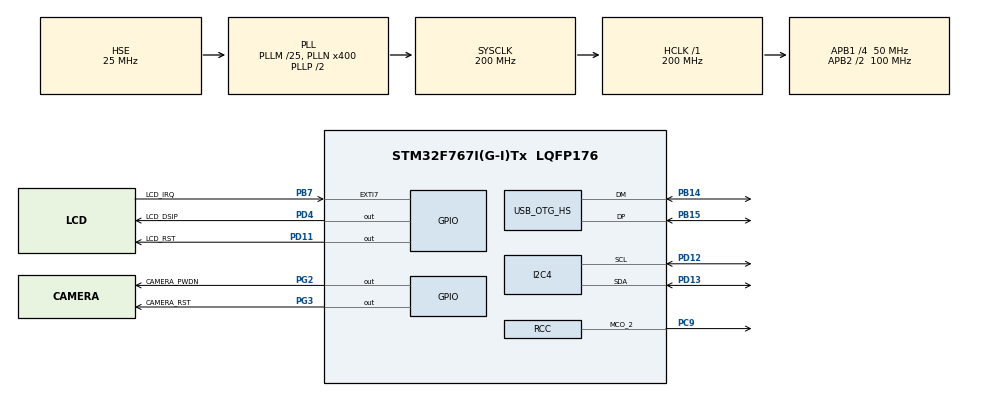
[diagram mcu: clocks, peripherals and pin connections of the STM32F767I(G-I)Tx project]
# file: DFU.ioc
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I2C4.Timing=0x00C0EAFF
Mcu.Family=STM32F7
Mcu.Name=STM32F767I(G-I)Tx
Mcu.Package=LQFP176
NVIC.OTG_HS_IRQn=true\:1\:0\:true\:false\:true\:false\:true
NVIC.PriorityGroup=NVIC_PRIORITYGROUP_4
NVIC.TIM1_UP_TIM10_IRQn=true\:0\:0\:false\:false\:true\:false\:true
NVIC.TimeBase=TIM1_UP_TIM10_IRQn
NVIC.TimeBaseIP=TIM1
PA0/WKUP.Mode=SYS_WakeUp0
PA0/WKUP.Signal=SYS_WKUP1
PA1.Signal=ETH_REF_CLK
PA10.Signal=USART1_RX
PA11.GPIO_Speed=GPIO_SPEED_FREQ_VERY_HIGH
PA11.Signal=LTDC_R4
PA12.GPIO_Speed=GPIO_SPEED_FREQ_VERY_HIGH
PA12.Signal=LTDC_R5
PA13.Mode=Serial_Wire
PA13.Signal=SYS_JTMS-SWDIO
PA14.Mode=Serial_Wire
PA14.Signal=SYS_JTCK-SWCLK
PA15.Signal=SYS_JTDI
PA2.Signal=ETH_MDIO
PA3.GPIO_Speed=GPIO_SPEED_FREQ_VERY_HIGH
PA3.Signal=LTDC_B5
PA4.Signal=DCMI_HSYNC
PA6.Signal=DCMI_PIXCLK
PA7.Signal=ETH_CRS_DV
PA8.Signal=RCC_MCO_1
PA9.Signal=USART1_TX
PB0.GPIO_Speed=GPIO_SPEED_FREQ_VERY_HIGH
PB0.Signal=LTDC_R3
PB1.GPIO_Speed=GPIO_SPEED_FREQ_VERY_HIGH
PB1.Signal=LTDC_R6
PB10.Signal=USART3_TX
PB11.Signal=ETH_TX_EN
PB14.Mode=Device_Only_FS
PB14.Signal=USB_OTG_HS_DM
PB15.Mode=Device_Only_FS
PB15.Signal=USB_OTG_HS_DP
PB2.Signal=QUADSPI_CLK
PB3.Signal=SYS_JTDO-SWO
PB4.Signal=SYS_JTRST
PB6.Signal=QUADSPI_BK1_NCS
PB7.GPIO_Label=LCD_IRQ
PB7.Signal=GPXTI7
PB8.GPIO_Speed=GPIO_SPEED_FREQ_VERY_HIGH
PB8.Signal=LTDC_B6
PB9.GPIO_Speed=GPIO_SPEED_FREQ_VERY_HIGH
PB9.Signal=LTDC_B7
PC0.Signal=FMC_SDNWE
PC1.Signal=ETH_MDC
PC10.Signal=SDMMC1_D2
PC11.Signal=SDMMC1_D3
PC12.Signal=SDMMC1_CK
PC13.Signal=RTC_TAMP1
PC14/OSC32_IN.Mode=LSE-External-Oscillator
PC14/OSC32_IN.Signal=RCC_OSC32_IN
PC15/OSC32_OUT.Mode=LSE-External-Oscillator
PC15/OSC32_OUT.Signal=RCC_OSC32_OUT
PC4.Signal=ETH_RXD0
PC5.Signal=ETH_RXD1
PC7.GPIO_Speed=GPIO_SPEED_FREQ_VERY_HIGH
PC7.Signal=LTDC_G6
PC8.Signal=SDMMC1_D0
PC9.Mode=Clock-out-2
PC9.Signal=RCC_MCO_2
PD0.Signal=FMC_D2_DA2
PD1.Signal=FMC_D3_DA3
PD10.Signal=FMC_D15_DA15
PD11.GPIO_Label=LCD_RST
PD11.Signal=GPIO_Output
PD12.Mode=I2C
PD12.Signal=I2C4_SCL
PD13.Mode=I2C
PD13.Signal=I2C4_SDA
PD14.Signal=FMC_D0_DA0
PD15.Signal=FMC_D1_DA1
PD2.Signal=SDMMC1_CMD
PD3.Signal=DCMI_D5
PD4.GPIO_Label=LCD_DSIP
PD4.Signal=GPIO_Output
PD5.Signal=USART2_TX
PD6.GPIO_Speed=GPIO_SPEED_FREQ_VERY_HIGH
PD6.Signal=LTDC_B2
PD8.Signal=FMC_D13_DA13
PD9.Signal=FMC_D14_DA14
PE0.Signal=FMC_NBL0
PE1.Signal=FMC_NBL1
PE10.Signal=FMC_D7_DA7
PE11.Signal=FMC_D8_DA8
PE12.Signal=FMC_D9_DA9
PE13.Signal=FMC_D10_DA10
PE14.Signal=FMC_D11_DA11
PE15.Signal=FMC_D12_DA12
PE4.GPIO_Speed=GPIO_SPEED_FREQ_VERY_HIGH
PE4.Signal=LTDC_B0
PE5.GPIO_Speed=GPIO_SPEED_FREQ_VERY_HIGH
PE5.Signal=LTDC_G0
PE6.GPIO_Speed=GPIO_SPEED_FREQ_VERY_HIGH
PE6.Signal=LTDC_G1
PE7.Signal=FMC_D4_DA4
PE8.Signal=FMC_D5_DA5
PE9.Signal=FMC_D6_DA6
PF0.Signal=FMC_A0
PF1.Signal=FMC_A1
PF10.GPIO_Speed=GPIO_SPEED_FREQ_VERY_HIGH
PF10.Signal=LTDC_DE
PF11.Signal=FMC_SDNRAS
PF12.Signal=FMC_A6
PF13.Signal=FMC_A7
PF14.Signal=FMC_A8
PF15.Signal=FMC_A9
PF2.Signal=FMC_A2
PF3.Signal=FMC_A3
PF4.Signal=FMC_A4
PF5.Signal=FMC_A5
PF6.Signal=QUADSPI_BK1_IO3
PF7.Signal=QUADSPI_BK1_IO2
PF8.Signal=QUADSPI_BK1_IO0
PF9.Signal=QUADSPI_BK1_IO1
PG0.Signal=FMC_A10
PG1.Signal=FMC_A11
PG10.GPIO_Speed=GPIO_SPEED_FREQ_VERY_HIGH
PG10.Signal=LTDC_G3
PG11.GPIO_Speed=GPIO_SPEED_FREQ_VERY_HIGH
PG11.Signal=LTDC_B3
PG12.GPIO_Speed=GPIO_SPEED_FREQ_VERY_HIGH
PG12.Signal=LTDC_B1
PG13.Signal=ETH_TXD0
PG14.Signal=ETH_TXD1
PG15.Signal=FMC_SDNCAS
PG2.GPIO_Label=CAMERA_PWDN
PG2.Signal=GPIO_Output
PG3.GPIO_Label=CAMERA_RST
PG3.Signal=GPIO_Output
PG4.Signal=FMC_A14_BA0
PG5.Signal=FMC_A15_BA1
PG6.GPIO_Speed=GPIO_SPEED_FREQ_VERY_HIGH
PG6.Signal=LTDC_R7
PG7.GPIO_Speed=GPIO_SPEED_FREQ_VERY_HIGH
PG7.Signal=LTDC_CLK
PG8.Signal=FMC_SDCLK
PH0/OSC_IN.Mode=HSE-External-Oscillator
PH0/OSC_IN.Signal=RCC_OSC_IN
PH1/OSC_OUT.Mode=HSE-External-Oscillator
PH1/OSC_OUT.Signal=RCC_OSC_OUT
PH10.Signal=DCMI_D1
PH11.Signal=DCMI_D2
PH12.Signal=DCMI_D3
PH13.GPIO_Speed=GPIO_SPEED_FREQ_VERY_HIGH
PH13.Signal=LTDC_G2
PH14.Signal=DCMI_D4
PH15.GPIO_Speed=GPIO_SPEED_FREQ_VERY_HIGH
PH15.Signal=LTDC_G4
PH2.GPIO_Speed=GPIO_SPEED_FREQ_VERY_HIGH
PH2.Signal=LTDC_R0
PH3.GPIO_Speed=GPIO_SPEED_FREQ_VERY_HIGH
PH3.Signal=LTDC_R1
PH4.Signal=I2C2_SCL
PH5.Signal=I2C2_SDA
PH6.Signal=FMC_SDNE1
PH7.Signal=FMC_SDCKE1
PH8.GPIO_Speed=GPIO_SPEED_FREQ_VERY_HIGH
PH8.Signal=LTDC_R2
PH9.Signal=DCMI_D0
PI0.GPIO_Speed=GPIO_SPEED_FREQ_VERY_HIGH
PI0.Signal=LTDC_G5
PI10.GPIO_Speed=GPIO_SPEED_FREQ_VERY_HIGH
PI10.Signal=LTDC_HSYNC
PI2.GPIO_Speed=GPIO_SPEED_FREQ_VERY_HIGH
PI2.Signal=LTDC_G7
PI4.GPIO_Speed=GPIO_SPEED_FREQ_VERY_HIGH
PI4.Signal=LTDC_B4
PI5.Signal=DCMI_VSYNC
PI6.Signal=DCMI_D6
PI7.Signal=DCMI_D7
PI9.GPIO_Speed=GPIO_SPEED_FREQ_VERY_HIGH
PI9.Signal=LTDC_VSYNC
ProjectManager.HeapSize=0x1000
ProjectManager.StackSize=0x1000
ProjectManager.TargetToolchain=MDK-ARM V5
RCC.AHBFreq_Value=200000000
RCC.APB1CLKDivider=RCC_HCLK_DIV4
RCC.APB1Freq_Value=50000000
RCC.APB1TimFreq_Value=100000000
RCC.APB2CLKDivider=RCC_HCLK_DIV2
RCC.APB2Freq_Value=100000000
RCC.APB2TimFreq_Value=200000000
RCC.CortexFreq_Value=200000000
RCC.EnbaleCSS=true
RCC.HCLKFreq_Value=200000000
RCC.HSE_VALUE=25000000
RCC.HSI_VALUE=16000000
RCC.PLL48CLockSelection=RCC_CLK48SOURCE_PLLSAIP
RCC.PLLI2SR=4
RCC.PLLM=25
RCC.PLLN=400
RCC.PLLQ=8
RCC.PLLSAIN=288
RCC.PLLSAIP=RCC_PLLSAIP_DIV6
RCC.PLLSAIR=3
RCC.PLLSourceVirtual=RCC_PLLSOURCE_HSE
RCC.RCC_MCO1Source=RCC_MCO1SOURCE_PLLCLK
RCC.RCC_MCO2Source=RCC_MCO2SOURCE_PLLI2SCLK
RCC.RCC_MCODiv1=RCC_MCODIV_4
RCC.RCC_MCODiv2=RCC_MCODIV_2
RCC.RTCClockSelection=RCC_RTCCLKSOURCE_LSE
RCC.SDMMCClockSelection=RCC_SDMMC1CLKSOURCE_CLK48
RCC.SYSCLKFreq_VALUE=200000000
RCC.SYSCLKSource=RCC_SYSCLKSOURCE_PLLCLK
RCC.USART1CLockSelection=RCC_USART1CLKSOURCE_SYSCLK
RCC.USBFreq_Value=48000000
RCC.VCOOutputFreq_Value=400000000
SH.FMC_A0.0=FMC_A0
SH.FMC_A1.0=FMC_A1
SH.FMC_A10.0=FMC_A10
SH.FMC_A11.0=FMC_A11
SH.FMC_A14_BA0.0=FMC_BA0
SH.FMC_A15_BA1.0=FMC_BA1
SH.FMC_A2.0=FMC_A2
SH.FMC_A3.0=FMC_A3
SH.FMC_A4.0=FMC_A4
SH.FMC_A5.0=FMC_A5
SH.FMC_A6.0=FMC_A6
SH.FMC_A7.0=FMC_A7
SH.FMC_A8.0=FMC_A8
SH.FMC_A9.0=FMC_A9
SH.FMC_D0_DA0.0=FMC_DA0
SH.FMC_D0_DA0.1=FMC_D0
SH.FMC_D10_DA10.0=FMC_DA10
SH.FMC_D10_DA10.1=FMC_D10
SH.FMC_D11_DA11.0=FMC_DA11
SH.FMC_D11_DA11.1=FMC_D11
SH.FMC_D12_DA12.0=FMC_DA12
SH.FMC_D12_DA12.1=FMC_D12
SH.FMC_D13_DA13.0=FMC_DA13
SH.FMC_D13_DA13.1=FMC_D13
SH.FMC_D14_DA14.0=FMC_DA14
SH.FMC_D14_DA14.1=FMC_D14
SH.FMC_D15_DA15.0=FMC_DA15
SH.FMC_D15_DA15.1=FMC_D15
SH.FMC_D1_DA1.0=FMC_DA1
SH.FMC_D1_DA1.1=FMC_D1
SH.FMC_D2_DA2.0=FMC_DA2
SH.FMC_D2_DA2.1=FMC_D2
SH.FMC_D3_DA3.0=FMC_DA3
SH.FMC_D3_DA3.1=FMC_D3
SH.FMC_D4_DA4.0=FMC_DA4
SH.FMC_D4_DA4.1=FMC_D4
SH.FMC_D5_DA5.0=FMC_DA5
SH.FMC_D5_DA5.1=FMC_D5
SH.FMC_D6_DA6.0=FMC_DA6
SH.FMC_D6_DA6.1=FMC_D6
SH.FMC_D7_DA7.0=FMC_DA7
SH.FMC_D7_DA7.1=FMC_D7
SH.FMC_D8_DA8.0=FMC_DA8
SH.FMC_D8_DA8.1=FMC_D8
SH.FMC_D9_DA9.0=FMC_DA9
SH.FMC_D9_DA9.1=FMC_D9
SH.FMC_NBL0.0=FMC_NBL0
SH.FMC_NBL1.0=FMC_NBL1
SH.FMC_SDCLK.0=FMC_SDCLK
SH.FMC_SDNCAS.0=FMC_SDNCAS
SH.FMC_SDNRAS.0=FMC_SDNRAS
SH.FMC_SDNWE.0=FMC_SDNWE
USB_DEVICE.CLASS_NAME_HS=DFU
USB_DEVICE.USBD_DFU_APP_DEFAULT_ADD-DFU_HS=0x08008000
USB_DEVICE.USBD_DFU_MEDIA-DFU_HS=@Internal Flash   /0x08000000/01*032Ka,03*032Kg,01*128Kg,03*256Kg
USB_DEVICE.VirtualMode-DFU_HS=Dfu
USB_DEVICE.VirtualModeHS=Dfu_HS
USB_OTG_HS.VirtualMode-Device_Only_FS=Device_Only_FS
VP_SYS_VS_tim1.Mode=TIM1
VP_USB_DEVICE_VS_USB_DEVICE_DFU_HS.Mode=DFU_HS
board=custom

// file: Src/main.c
/* USER CODE BEGIN Header */
/**
  ******************************************************************************
  * @file           : main.c
  * @brief          : Main program body
  ******************************************************************************
  * @attention
  *
  * <h2><center>&copy; Copyright (c) 2020 STMicroelectronics.
  * All rights reserved.</center></h2>
  *
  * This software component is licensed by ST under Ultimate Liberty license
  * SLA0044, the "License"; You may not use this file except in compliance with
  * the License. You may obtain a copy of the License at:
  *                             www.st.com/SLA0044
  *
  ******************************************************************************
  */
/* USER CODE END Header */

#include "main.h"
#include "usb_device.h"

/* USER CODE BEGIN Includes */

#include "usbd_core.h"
#include "usbd_desc.h"
#include "usbd_dfu.h"
#include "usbd_dfu_if.h"

/* USER CODE END Includes */

I2C_HandleTypeDef hi2c4;

/* USER CODE BEGIN PV */

pFunction JumpToApplication;
uint32_t JumpAddress;

/* USER CODE END PV */

void SystemClock_Config(void);
static void MX_GPIO_Init(void);
static void MX_I2C4_Init(void);

int main(void)
{

  /* MCU Configuration--------------------------------------------------------*/

  /* Reset of all peripherals, Initializes the Flash interface and the Systick. */
  HAL_Init();

  /* Configure the system clock */
  SystemClock_Config();

  /* USER CODE BEGIN SysInit */

  /* Check if the KEY Button is pressed */
  if(HAL_GPIO_ReadPin(GPIOA, GPIO_PIN_0) == 0x00)
  {
    /* Test if user code is programmed starting from USBD_DFU_APP_DEFAULT_ADD address */
    if(((*(__IO uint32_t*)USBD_DFU_APP_DEFAULT_ADD) & 0x2FFE0000 ) == 0x20000000)
    {
      /* Jump to user application */
      JumpAddress = *(__IO uint32_t*) (USBD_DFU_APP_DEFAULT_ADD + 4);
      JumpToApplication = (pFunction) JumpAddress;

      /* Initialize user application's Stack Pointer */
      __set_MSP(*(__IO uint32_t*) USBD_DFU_APP_DEFAULT_ADD);
      JumpToApplication();
    }
  }

  /* USER CODE END SysInit */

  /* Initialize all configured peripherals */
  MX_GPIO_Init();
  MX_I2C4_Init();
  MX_USB_DEVICE_Init();

  /* Infinite loop */
  while (1)
  {

  }
}

void SystemClock_Config(void)
{
  RCC_OscInitTypeDef RCC_OscInitStruct = {0};
  RCC_ClkInitTypeDef RCC_ClkInitStruct = {0};
  RCC_PeriphCLKInitTypeDef PeriphClkInitStruct = {0};

  /** Configure LSE Drive Capability
  */
  HAL_PWR_EnableBkUpAccess();
  /** Configure the main internal regulator output voltage
  */
  __HAL_RCC_PWR_CLK_ENABLE();
  __HAL_PWR_VOLTAGESCALING_CONFIG(PWR_REGULATOR_VOLTAGE_SCALE1);
  /** Initializes the CPU, AHB and APB busses clocks
  */
  RCC_OscInitStruct.OscillatorType = RCC_OSCILLATORTYPE_HSE;
  RCC_OscInitStruct.HSEState = RCC_HSE_ON;
  RCC_OscInitStruct.PLL.PLLState = RCC_PLL_ON;
  RCC_OscInitStruct.PLL.PLLSource = RCC_PLLSOURCE_HSE;
  RCC_OscInitStruct.PLL.PLLM = 25;
  RCC_OscInitStruct.PLL.PLLN = 400;
  RCC_OscInitStruct.PLL.PLLP = RCC_PLLP_DIV2;
  RCC_OscInitStruct.PLL.PLLQ = 8;
  if (HAL_RCC_OscConfig(&RCC_OscInitStruct) != HAL_OK)
  {
    Error_Handler();
  }
  /** Activate the Over-Drive mode
  */
  if (HAL_PWREx_EnableOverDrive() != HAL_OK)
  {
    Error_Handler();
  }
  /** Initializes the CPU, AHB and APB busses clocks
  */
  RCC_ClkInitStruct.ClockType = RCC_CLOCKTYPE_HCLK|RCC_CLOCKTYPE_SYSCLK
                              |RCC_CLOCKTYPE_PCLK1|RCC_CLOCKTYPE_PCLK2;
  RCC_ClkInitStruct.SYSCLKSource = RCC_SYSCLKSOURCE_PLLCLK;
  RCC_ClkInitStruct.AHBCLKDivider = RCC_SYSCLK_DIV1;
  RCC_ClkInitStruct.APB1CLKDivider = RCC_HCLK_DIV4;
  RCC_ClkInitStruct.APB2CLKDivider = RCC_HCLK_DIV2;

  if (HAL_RCC_ClockConfig(&RCC_ClkInitStruct, FLASH_LATENCY_6) != HAL_OK)
  {
    Error_Handler();
  }
  PeriphClkInitStruct.PeriphClockSelection = RCC_PERIPHCLK_PLLI2S|RCC_PERIPHCLK_I2C4
                              |RCC_PERIPHCLK_CLK48;
  PeriphClkInitStruct.PLLI2S.PLLI2SN = 192;
  PeriphClkInitStruct.PLLI2S.PLLI2SP = RCC_PLLP_DIV2;
  PeriphClkInitStruct.PLLI2S.PLLI2SR = 4;
  PeriphClkInitStruct.PLLI2S.PLLI2SQ = 2;
  PeriphClkInitStruct.PLLSAI.PLLSAIN = 288;
  PeriphClkInitStruct.PLLSAI.PLLSAIR = 3;
  PeriphClkInitStruct.PLLSAI.PLLSAIQ = 2;
  PeriphClkInitStruct.PLLSAI.PLLSAIP = RCC_PLLSAIP_DIV6;
  PeriphClkInitStruct.PLLI2SDivQ = 1;
  PeriphClkInitStruct.PLLSAIDivQ = 1;
  PeriphClkInitStruct.PLLSAIDivR = RCC_PLLSAIDIVR_2;
  PeriphClkInitStruct.I2c4ClockSelection = RCC_I2C4CLKSOURCE_PCLK1;
  PeriphClkInitStruct.Clk48ClockSelection = RCC_CLK48SOURCE_PLLSAIP;
  if (HAL_RCCEx_PeriphCLKConfig(&PeriphClkInitStruct) != HAL_OK)
  {
    Error_Handler();
  }
  HAL_RCC_MCOConfig(RCC_MCO2, RCC_MCO2SOURCE_PLLI2SCLK, RCC_MCODIV_2);
  /** Enables the Clock Security System
  */
  HAL_RCC_EnableCSS();
}

static void MX_I2C4_Init(void)
{

  hi2c4.Instance = I2C4;
  hi2c4.Init.Timing = 0x00C0EAFF;
  hi2c4.Init.OwnAddress1 = 0;
  hi2c4.Init.AddressingMode = I2C_ADDRESSINGMODE_7BIT;
  hi2c4.Init.DualAddressMode = I2C_DUALADDRESS_DISABLE;
  hi2c4.Init.OwnAddress2 = 0;
  hi2c4.Init.OwnAddress2Masks = I2C_OA2_NOMASK;
  hi2c4.Init.GeneralCallMode = I2C_GENERALCALL_DISABLE;
  hi2c4.Init.NoStretchMode = I2C_NOSTRETCH_DISABLE;
  if (HAL_I2C_Init(&hi2c4) != HAL_OK)
  {
    Error_Handler();
  }
  /** Configure Analogue filter
  */
  if (HAL_I2CEx_ConfigAnalogFilter(&hi2c4, I2C_ANALOGFILTER_ENABLE) != HAL_OK)
  {
    Error_Handler();
  }
  /** Configure Digital filter
  */
  if (HAL_I2CEx_ConfigDigitalFilter(&hi2c4, 0) != HAL_OK)
  {
    Error_Handler();
  }

}

static void MX_GPIO_Init(void)
{
  GPIO_InitTypeDef GPIO_InitStruct = {0};

  /* GPIO Ports Clock Enable */
  __HAL_RCC_GPIOE_CLK_ENABLE();
  __HAL_RCC_GPIOC_CLK_ENABLE();
  __HAL_RCC_GPIOI_CLK_ENABLE();
  __HAL_RCC_GPIOF_CLK_ENABLE();
  __HAL_RCC_GPIOH_CLK_ENABLE();
  __HAL_RCC_GPIOA_CLK_ENABLE();
  __HAL_RCC_GPIOB_CLK_ENABLE();
  __HAL_RCC_GPIOG_CLK_ENABLE();
  __HAL_RCC_GPIOD_CLK_ENABLE();

  /*Configure GPIO pin Output Level */
  HAL_GPIO_WritePin(GPIOD, LCD_RST_Pin|LCD_DSIP_Pin, GPIO_PIN_RESET);

  /*Configure GPIO pin Output Level */
  HAL_GPIO_WritePin(GPIOG, CAMERA_PWDN_Pin|CAMERA_RST_Pin, GPIO_PIN_RESET);

  /*Configure GPIO pins : PE4 PE5 PE6 */
  GPIO_InitStruct.Pin = GPIO_PIN_4|GPIO_PIN_5|GPIO_PIN_6;
  GPIO_InitStruct.Mode = GPIO_MODE_AF_PP;
  GPIO_InitStruct.Pull = GPIO_NOPULL;
  GPIO_InitStruct.Speed = GPIO_SPEED_FREQ_VERY_HIGH;
  GPIO_InitStruct.Alternate = GPIO_AF14_LTDC;
  HAL_GPIO_Init(GPIOE, &GPIO_InitStruct);

  /*Configure GPIO pins : PI9 PI10 PI0 PI2
                           PI4 */
  GPIO_InitStruct.Pin = GPIO_PIN_9|GPIO_PIN_10|GPIO_PIN_0|GPIO_PIN_2
                          |GPIO_PIN_4;
  GPIO_InitStruct.Mode = GPIO_MODE_AF_PP;
  GPIO_InitStruct.Pull = GPIO_NOPULL;
  GPIO_InitStruct.Speed = GPIO_SPEED_FREQ_VERY_HIGH;
  GPIO_InitStruct.Alternate = GPIO_AF14_LTDC;
  HAL_GPIO_Init(GPIOI, &GPIO_InitStruct);

  /*Configure GPIO pins : PF0 PF1 PF2 PF3
                           PF4 PF5 PF11 PF12
                           PF13 PF14 PF15 */
  GPIO_InitStruct.Pin = GPIO_PIN_0|GPIO_PIN_1|GPIO_PIN_2|GPIO_PIN_3
                          |GPIO_PIN_4|GPIO_PIN_5|GPIO_PIN_11|GPIO_PIN_12
                          |GPIO_PIN_13|GPIO_PIN_14|GPIO_PIN_15;
  GPIO_InitStruct.Mode = GPIO_MODE_AF_PP;
  GPIO_InitStruct.Pull = GPIO_NOPULL;
  GPIO_InitStruct.Speed = GPIO_SPEED_FREQ_VERY_HIGH;
  GPIO_InitStruct.Alternate = GPIO_AF12_FMC;
  HAL_GPIO_Init(GPIOF, &GPIO_InitStruct);

  /*Configure GPIO pins : PF6 PF7 */
  GPIO_InitStruct.Pin = GPIO_PIN_6|GPIO_PIN_7;
  GPIO_InitStruct.Mode = GPIO_MODE_AF_PP;
  GPIO_InitStruct.Pull = GPIO_NOPULL;
  GPIO_InitStruct.Speed = GPIO_SPEED_FREQ_VERY_HIGH;
  GPIO_InitStruct.Alternate = GPIO_AF9_QUADSPI;
  HAL_GPIO_Init(GPIOF, &GPIO_InitStruct);

  /*Configure GPIO pins : PF8 PF9 */
  GPIO_InitStruct.Pin = GPIO_PIN_8|GPIO_PIN_9;
  GPIO_InitStruct.Mode = GPIO_MODE_AF_PP;
  GPIO_InitStruct.Pull = GPIO_NOPULL;
  GPIO_InitStruct.Speed = GPIO_SPEED_FREQ_VERY_HIGH;
  GPIO_InitStruct.Alternate = GPIO_AF10_QUADSPI;
  HAL_GPIO_Init(GPIOF, &GPIO_InitStruct);

  /*Configure GPIO pin : PF10 */
  GPIO_InitStruct.Pin = GPIO_PIN_10;
  GPIO_InitStruct.Mode = GPIO_MODE_AF_PP;
  GPIO_InitStruct.Pull = GPIO_NOPULL;
  GPIO_InitStruct.Speed = GPIO_SPEED_FREQ_VERY_HIGH;
  GPIO_InitStruct.Alternate = GPIO_AF14_LTDC;
  HAL_GPIO_Init(GPIOF, &GPIO_InitStruct);

  /*Configure GPIO pin : PC0 */
  GPIO_InitStruct.Pin = GPIO_PIN_0;
  GPIO_InitStruct.Mode = GPIO_MODE_AF_PP;
  GPIO_InitStruct.Pull = GPIO_NOPULL;
  GPIO_InitStruct.Speed = GPIO_SPEED_FREQ_VERY_HIGH;
  GPIO_InitStruct.Alternate = GPIO_AF12_FMC;
  HAL_GPIO_Init(GPIOC, &GPIO_InitStruct);

  /*Configure GPIO pins : PC1 PC4 PC5 */
  GPIO_InitStruct.Pin = GPIO_PIN_1|GPIO_PIN_4|GPIO_PIN_5;
  GPIO_InitStruct.Mode = GPIO_MODE_AF_PP;
  GPIO_InitStruct.Pull = GPIO_NOPULL;
  GPIO_InitStruct.Speed = GPIO_SPEED_FREQ_VERY_HIGH;
  GPIO_InitStruct.Alternate = GPIO_AF11_ETH;
  HAL_GPIO_Init(GPIOC, &GPIO_InitStruct);

  /*Configure GPIO pins : PA1 PA2 PA7 */
  GPIO_InitStruct.Pin = GPIO_PIN_1|GPIO_PIN_2|GPIO_PIN_7;
  GPIO_InitStruct.Mode = GPIO_MODE_AF_PP;
  GPIO_InitStruct.Pull = GPIO_NOPULL;
  GPIO_InitStruct.Speed = GPIO_SPEED_FREQ_VERY_HIGH;
  GPIO_InitStruct.Alternate = GPIO_AF11_ETH;
  HAL_GPIO_Init(GPIOA, &GPIO_InitStruct);

  /*Configure GPIO pins : PH2 PH3 PH8 PH13
                           PH15 */
  GPIO_InitStruct.Pin = GPIO_PIN_2|GPIO_PIN_3|GPIO_PIN_8|GPIO_PIN_13
                          |GPIO_PIN_15;
  GPIO_InitStruct.Mode = GPIO_MODE_AF_PP;
  GPIO_InitStruct.Pull = GPIO_NOPULL;
  GPIO_InitStruct.Speed = GPIO_SPEED_FREQ_VERY_HIGH;
  GPIO_InitStruct.Alternate = GPIO_AF14_LTDC;
  HAL_GPIO_Init(GPIOH, &GPIO_InitStruct);

  /*Configure GPIO pins : PH4 PH5 */
  GPIO_InitStruct.Pin = GPIO_PIN_4|GPIO_PIN_5;
  GPIO_InitStruct.Mode = GPIO_MODE_AF_OD;
  GPIO_InitStruct.Pull = GPIO_PULLUP;
  GPIO_InitStruct.Speed = GPIO_SPEED_FREQ_VERY_HIGH;
  GPIO_InitStruct.Alternate = GPIO_AF4_I2C2;
  HAL_GPIO_Init(GPIOH, &GPIO_InitStruct);

  /*Configure GPIO pins : PA3 PA11 PA12 */
  GPIO_InitStruct.Pin = GPIO_PIN_3|GPIO_PIN_11|GPIO_PIN_12;
  GPIO_InitStruct.Mode = GPIO_MODE_AF_PP;
  GPIO_InitStruct.Pull = GPIO_NOPULL;
  GPIO_InitStruct.Speed = GPIO_SPEED_FREQ_VERY_HIGH;
  GPIO_InitStruct.Alternate = GPIO_AF14_LTDC;
  HAL_GPIO_Init(GPIOA, &GPIO_InitStruct);

  /*Configure GPIO pins : PA4 PA6 */
  GPIO_InitStruct.Pin = GPIO_PIN_4|GPIO_PIN_6;
  GPIO_InitStruct.Mode = GPIO_MODE_AF_PP;
  GPIO_InitStruct.Pull = GPIO_NOPULL;
  GPIO_InitStruct.Speed = GPIO_SPEED_FREQ_LOW;
  GPIO_InitStruct.Alternate = GPIO_AF13_DCMI;
  HAL_GPIO_Init(GPIOA, &GPIO_InitStruct);

  /*Configure GPIO pins : PB0 PB1 */
  GPIO_InitStruct.Pin = GPIO_PIN_0|GPIO_PIN_1;
  GPIO_InitStruct.Mode = GPIO_MODE_AF_PP;
  GPIO_InitStruct.Pull = GPIO_NOPULL;
  GPIO_InitStruct.Speed = GPIO_SPEED_FREQ_VERY_HIGH;
  GPIO_InitStruct.Alternate = GPIO_AF9_LTDC;
  HAL_GPIO_Init(GPIOB, &GPIO_InitStruct);

  /*Configure GPIO pin : PB2 */
  GPIO_InitStruct.Pin = GPIO_PIN_2;
  GPIO_InitStruct.Mode = GPIO_MODE_AF_PP;
  GPIO_InitStruct.Pull = GPIO_NOPULL;
  GPIO_InitStruct.Speed = GPIO_SPEED_FREQ_VERY_HIGH;
  GPIO_InitStruct.Alternate = GPIO_AF9_QUADSPI;
  HAL_GPIO_Init(GPIOB, &GPIO_InitStruct);

  /*Configure GPIO pins : PG0 PG1 PG4 PG5
                           PG8 PG15 */
  GPIO_InitStruct.Pin = GPIO_PIN_0|GPIO_PIN_1|GPIO_PIN_4|GPIO_PIN_5
                          |GPIO_PIN_8|GPIO_PIN_15;
  GPIO_InitStruct.Mode = GPIO_MODE_AF_PP;
  GPIO_InitStruct.Pull = GPIO_NOPULL;
  GPIO_InitStruct.Speed = GPIO_SPEED_FREQ_VERY_HIGH;
  GPIO_InitStruct.Alternate = GPIO_AF12_FMC;
  HAL_GPIO_Init(GPIOG, &GPIO_InitStruct);

  /*Configure GPIO pins : PE7 PE8 PE9 PE10
                           PE11 PE12 PE13 PE14
                           PE15 PE0 PE1 */
  GPIO_InitStruct.Pin = GPIO_PIN_7|GPIO_PIN_8|GPIO_PIN_9|GPIO_PIN_10
                          |GPIO_PIN_11|GPIO_PIN_12|GPIO_PIN_13|GPIO_PIN_14
                          |GPIO_PIN_15|GPIO_PIN_0|GPIO_PIN_1;
  GPIO_InitStruct.Mode = GPIO_MODE_AF_PP;
  GPIO_InitStruct.Pull = GPIO_NOPULL;
  GPIO_InitStruct.Speed = GPIO_SPEED_FREQ_VERY_HIGH;
  GPIO_InitStruct.Alternate = GPIO_AF12_FMC;
  HAL_GPIO_Init(GPIOE, &GPIO_InitStruct);

  /*Configure GPIO pin : PB10 */
  GPIO_InitStruct.Pin = GPIO_PIN_10;
  GPIO_InitStruct.Mode = GPIO_MODE_AF_PP;
  GPIO_InitStruct.Pull = GPIO_NOPULL;
  GPIO_InitStruct.Speed = GPIO_SPEED_FREQ_VERY_HIGH;
  GPIO_InitStruct.Alternate = GPIO_AF7_USART3;
  HAL_GPIO_Init(GPIOB, &GPIO_InitStruct);

  /*Configure GPIO pin : PB11 */
  GPIO_InitStruct.Pin = GPIO_PIN_11;
  GPIO_InitStruct.Mode = GPIO_MODE_AF_PP;
  GPIO_InitStruct.Pull = GPIO_NOPULL;
  GPIO_InitStruct.Speed = GPIO_SPEED_FREQ_VERY_HIGH;
  GPIO_InitStruct.Alternate = GPIO_AF11_ETH;
  HAL_GPIO_Init(GPIOB, &GPIO_InitStruct);

  /*Configure GPIO pins : PH6 PH7 */
  GPIO_InitStruct.Pin = GPIO_PIN_6|GPIO_PIN_7;
  GPIO_InitStruct.Mode = GPIO_MODE_AF_PP;
  GPIO_InitStruct.Pull = GPIO_NOPULL;
  GPIO_InitStruct.Speed = GPIO_SPEED_FREQ_VERY_HIGH;
  GPIO_InitStruct.Alternate = GPIO_AF12_FMC;
  HAL_GPIO_Init(GPIOH, &GPIO_InitStruct);

  /*Configure GPIO pins : PH9 PH10 PH11 PH12
                           PH14 */
  GPIO_InitStruct.Pin = GPIO_PIN_9|GPIO_PIN_10|GPIO_PIN_11|GPIO_PIN_12
                          |GPIO_PIN_14;
  GPIO_InitStruct.Mode = GPIO_MODE_AF_PP;
  GPIO_InitStruct.Pull = GPIO_NOPULL;
  GPIO_InitStruct.Speed = GPIO_SPEED_FREQ_LOW;
  GPIO_InitStruct.Alternate = GPIO_AF13_DCMI;
  HAL_GPIO_Init(GPIOH, &GPIO_InitStruct);

  /*Configure GPIO pins : PD8 PD9 PD10 PD14
                           PD15 PD0 PD1 */
  GPIO_InitStruct.Pin = GPIO_PIN_8|GPIO_PIN_9|GPIO_PIN_10|GPIO_PIN_14
                          |GPIO_PIN_15|GPIO_PIN_0|GPIO_PIN_1;
  GPIO_InitStruct.Mode = GPIO_MODE_AF_PP;
  GPIO_InitStruct.Pull = GPIO_NOPULL;
  GPIO_InitStruct.Speed = GPIO_SPEED_FREQ_VERY_HIGH;
  GPIO_InitStruct.Alternate = GPIO_AF12_FMC;
  HAL_GPIO_Init(GPIOD, &GPIO_InitStruct);

  /*Configure GPIO pins : LCD_RST_Pin LCD_DSIP_Pin */
  GPIO_InitStruct.Pin = LCD_RST_Pin|LCD_DSIP_Pin;
  GPIO_InitStruct.Mode = GPIO_MODE_OUTPUT_PP;
  GPIO_InitStruct.Pull = GPIO_NOPULL;
  GPIO_InitStruct.Speed = GPIO_SPEED_FREQ_LOW;
  HAL_GPIO_Init(GPIOD, &GPIO_InitStruct);

  /*Configure GPIO pins : CAMERA_PWDN_Pin CAMERA_RST_Pin */
  GPIO_InitStruct.Pin = CAMERA_PWDN_Pin|CAMERA_RST_Pin;
  GPIO_InitStruct.Mode = GPIO_MODE_OUTPUT_PP;
  GPIO_InitStruct.Pull = GPIO_NOPULL;
  GPIO_InitStruct.Speed = GPIO_SPEED_FREQ_LOW;
  HAL_GPIO_Init(GPIOG, &GPIO_InitStruct);

  /*Configure GPIO pins : PG6 PG7 PG11 PG12 */
  GPIO_InitStruct.Pin = GPIO_PIN_6|GPIO_PIN_7|GPIO_PIN_11|GPIO_PIN_12;
  GPIO_InitStruct.Mode = GPIO_MODE_AF_PP;
  GPIO_InitStruct.Pull = GPIO_NOPULL;
  GPIO_InitStruct.Speed = GPIO_SPEED_FREQ_VERY_HIGH;
  GPIO_InitStruct.Alternate = GPIO_AF14_LTDC;
  HAL_GPIO_Init(GPIOG, &GPIO_InitStruct);

  /*Configure GPIO pin : PC7 */
  GPIO_InitStruct.Pin = GPIO_PIN_7;
  GPIO_InitStruct.Mode = GPIO_MODE_AF_PP;
  GPIO_InitStruct.Pull = GPIO_NOPULL;
  GPIO_InitStruct.Speed = GPIO_SPEED_FREQ_VERY_HIGH;
  GPIO_InitStruct.Alternate = GPIO_AF14_LTDC;
  HAL_GPIO_Init(GPIOC, &GPIO_InitStruct);

  /*Configure GPIO pins : PC8 PC10 PC11 PC12 */
  GPIO_InitStruct.Pin = GPIO_PIN_8|GPIO_PIN_10|GPIO_PIN_11|GPIO_PIN_12;
  GPIO_InitStruct.Mode = GPIO_MODE_AF_PP;
  GPIO_InitStruct.Pull = GPIO_NOPULL;
  GPIO_InitStruct.Speed = GPIO_SPEED_FREQ_VERY_HIGH;
  GPIO_InitStruct.Alternate = GPIO_AF12_SDMMC1;
  HAL_GPIO_Init(GPIOC, &GPIO_InitStruct);

  /*Configure GPIO pin : PC9 */
  GPIO_InitStruct.Pin = GPIO_PIN_9;
  GPIO_InitStruct.Mode = GPIO_MODE_AF_PP;
  GPIO_InitStruct.Pull = GPIO_NOPULL;
  GPIO_InitStruct.Speed = GPIO_SPEED_FREQ_LOW;
  GPIO_InitStruct.Alternate = GPIO_AF0_MCO;
  HAL_GPIO_Init(GPIOC, &GPIO_InitStruct);

  /*Configure GPIO pin : PA8 */
  GPIO_InitStruct.Pin = GPIO_PIN_8;
  GPIO_InitStruct.Mode = GPIO_MODE_AF_PP;
  GPIO_InitStruct.Pull = GPIO_NOPULL;
  GPIO_InitStruct.Speed = GPIO_SPEED_FREQ_LOW;
  GPIO_InitStruct.Alternate = GPIO_AF0_MCO;
  HAL_GPIO_Init(GPIOA, &GPIO_InitStruct);

  /*Configure GPIO pins : PA9 PA10 */
  GPIO_InitStruct.Pin = GPIO_PIN_9|GPIO_PIN_10;
  GPIO_InitStruct.Mode = GPIO_MODE_AF_PP;
  GPIO_InitStruct.Pull = GPIO_NOPULL;
  GPIO_InitStruct.Speed = GPIO_SPEED_FREQ_VERY_HIGH;
  GPIO_InitStruct.Alternate = GPIO_AF7_USART1;
  HAL_GPIO_Init(GPIOA, &GPIO_InitStruct);

  /*Configure GPIO pin : PD2 */
  GPIO_InitStruct.Pin = GPIO_PIN_2;
  GPIO_InitStruct.Mode = GPIO_MODE_AF_PP;
  GPIO_InitStruct.Pull = GPIO_NOPULL;
  GPIO_InitStruct.Speed = GPIO_SPEED_FREQ_VERY_HIGH;
  GPIO_InitStruct.Alternate = GPIO_AF12_SDMMC1;
  HAL_GPIO_Init(GPIOD, &GPIO_InitStruct);

  /*Configure GPIO pin : PD3 */
  GPIO_InitStruct.Pin = GPIO_PIN_3;
  GPIO_InitStruct.Mode = GPIO_MODE_AF_PP;
  GPIO_InitStruct.Pull = GPIO_NOPULL;
  GPIO_InitStruct.Speed = GPIO_SPEED_FREQ_LOW;
  GPIO_InitStruct.Alternate = GPIO_AF13_DCMI;
  HAL_GPIO_Init(GPIOD, &GPIO_InitStruct);

  /*Configure GPIO pin : PD5 */
  GPIO_InitStruct.Pin = GPIO_PIN_5;
  GPIO_InitStruct.Mode = GPIO_MODE_AF_PP;
  GPIO_InitStruct.Pull = GPIO_NOPULL;
  GPIO_InitStruct.Speed = GPIO_SPEED_FREQ_VERY_HIGH;
  GPIO_InitStruct.Alternate = GPIO_AF7_USART2;
  HAL_GPIO_Init(GPIOD, &GPIO_InitStruct);

  /*Configure GPIO pin : PD6 */
  GPIO_InitStruct.Pin = GPIO_PIN_6;
  GPIO_InitStruct.Mode = GPIO_MODE_AF_PP;
  GPIO_InitStruct.Pull = GPIO_NOPULL;
  GPIO_InitStruct.Speed = GPIO_SPEED_FREQ_VERY_HIGH;
  GPIO_InitStruct.Alternate = GPIO_AF14_LTDC;
  HAL_GPIO_Init(GPIOD, &GPIO_InitStruct);

  /*Configure GPIO pin : PG10 */
  GPIO_InitStruct.Pin = GPIO_PIN_10;
  GPIO_InitStruct.Mode = GPIO_MODE_AF_PP;
  GPIO_InitStruct.Pull = GPIO_NOPULL;
  GPIO_InitStruct.Speed = GPIO_SPEED_FREQ_VERY_HIGH;
  GPIO_InitStruct.Alternate = GPIO_AF9_LTDC;
  HAL_GPIO_Init(GPIOG, &GPIO_InitStruct);

  /*Configure GPIO pins : PG13 PG14 */
  GPIO_InitStruct.Pin = GPIO_PIN_13|GPIO_PIN_14;
  GPIO_InitStruct.Mode = GPIO_MODE_AF_PP;
  GPIO_InitStruct.Pull = GPIO_NOPULL;
  GPIO_InitStruct.Speed = GPIO_SPEED_FREQ_VERY_HIGH;
  GPIO_InitStruct.Alternate = GPIO_AF11_ETH;
  HAL_GPIO_Init(GPIOG, &GPIO_InitStruct);

  /*Configure GPIO pin : PB6 */
  GPIO_InitStruct.Pin = GPIO_PIN_6;
  GPIO_InitStruct.Mode = GPIO_MODE_AF_PP;
  GPIO_InitStruct.Pull = GPIO_NOPULL;
  GPIO_InitStruct.Speed = GPIO_SPEED_FREQ_VERY_HIGH;
  GPIO_InitStruct.Alternate = GPIO_AF10_QUADSPI;
  HAL_GPIO_Init(GPIOB, &GPIO_InitStruct);

  /*Configure GPIO pin : LCD_IRQ_Pin */
  GPIO_InitStruct.Pin = LCD_IRQ_Pin;
  GPIO_InitStruct.Mode = GPIO_MODE_IT_RISING;
  GPIO_InitStruct.Pull = GPIO_NOPULL;
  HAL_GPIO_Init(LCD_IRQ_GPIO_Port, &GPIO_InitStruct);

  /*Configure GPIO pins : PB8 PB9 */
  GPIO_InitStruct.Pin = GPIO_PIN_8|GPIO_PIN_9;
  GPIO_InitStruct.Mode = GPIO_MODE_AF_PP;
  GPIO_InitStruct.Pull = GPIO_NOPULL;
  GPIO_InitStruct.Speed = GPIO_SPEED_FREQ_VERY_HIGH;
  GPIO_InitStruct.Alternate = GPIO_AF14_LTDC;
  HAL_GPIO_Init(GPIOB, &GPIO_InitStruct);

  /*Configure GPIO pins : PI5 PI6 PI7 */
  GPIO_InitStruct.Pin = GPIO_PIN_5|GPIO_PIN_6|GPIO_PIN_7;
  GPIO_InitStruct.Mode = GPIO_MODE_AF_PP;
  GPIO_InitStruct.Pull = GPIO_NOPULL;
  GPIO_InitStruct.Speed = GPIO_SPEED_FREQ_LOW;
  GPIO_InitStruct.Alternate = GPIO_AF13_DCMI;
  HAL_GPIO_Init(GPIOI, &GPIO_InitStruct);

}

void HAL_TIM_PeriodElapsedCallback(TIM_HandleTypeDef *htim)
{
  if (htim->Instance == TIM1) {
    HAL_IncTick();
  }
}

void Error_Handler(void)
{
}

/************************ (C) COPYRIGHT STMicroelectronics *****END OF FILE****/
